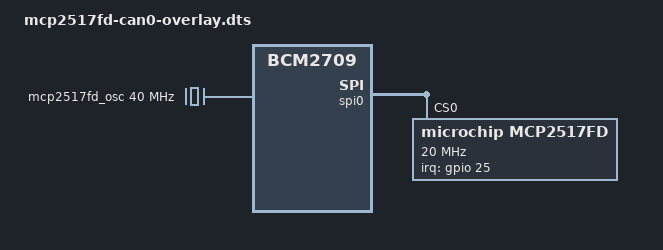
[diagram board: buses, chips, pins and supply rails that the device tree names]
/*
 * Device tree overlay for mcp251x/mcp2517fd on spi0.0
 */

/dts-v1/;
/plugin/;

/ {
    compatible = "brcm,bcm2835", "brcm,bcm2836", "brcm,bcm2708", "brcm,bcm2709";
    /* disable spi-dev for spi0.0 */

    fragment@0{
	target = <&spidev0>;
	__overlay__ {
	    status = "disabled";
	};
    };

    /* the interrupt pin of the can-controller */
    fragment@1 {
        target = <&gpio>;
        __overlay__ {
            int_pins: int_pins {
                brcm,pins = <25>;
                brcm,function = <0>; /* input */
            };
        };
    };

    /* the clock/oscillator of the can-controller */
    fragment@2 {
        target-path = "/clocks";
        __overlay__ {
            /* external 20M oscillator of mcp2517fd on SPI0.0 */
            mcp2517fd_osc: mcp2517fd_osc {
                compatible = "fixed-clock";
                #clock-cells = <0>;
                clock-frequency  = <40000000>;
            };
        };
    };

    /* the spi config of the can-controller itself binding everything together */
    fragment@3 {
        target = <&spi0>;
        can_overlay:__overlay__ {
            /* needed to avoid dtc warning */
            #address-cells = <1>;
            #size-cells = <0>;
            status = "okay";
            mcp2517fd: mcp2517fd@0 {
                reg = <0>;
                compatible = "microchip,mcp2517fd";
                pinctrl-names = "default";
                pinctrl-0 = <&int_pins>;
                spi-max-frequency = <20000000>;
                interrupt-parent = <&gpio>;
                interrupts = <25 8>; /* IRQ_TYPE_LEVEL_LOW */
                clocks = <&mcp2517fd_osc>;
            };
        };
    };
    __overrides__ {
   bus-name = <&can_overlay>,"SeeedStudio.com";
	 };
};
